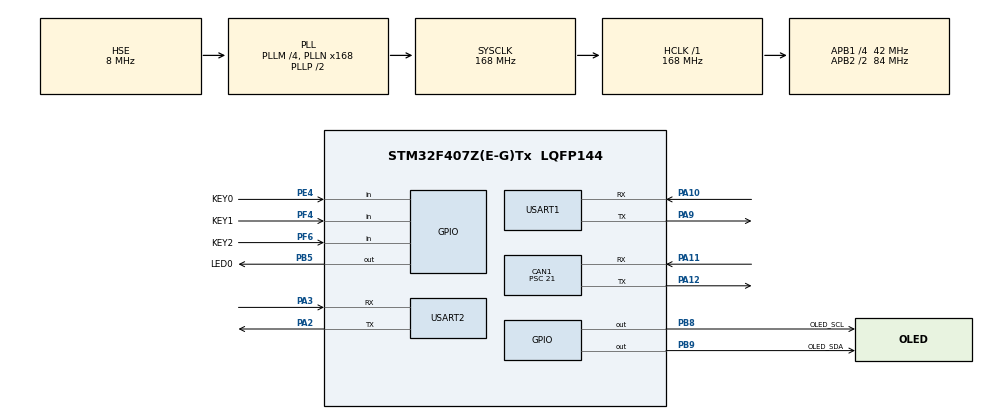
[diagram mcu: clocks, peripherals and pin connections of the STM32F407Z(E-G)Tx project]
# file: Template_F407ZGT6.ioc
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CAN1.BS1=CAN_BS1_13TQ
CAN1.BS2=CAN_BS2_2TQ
CAN1.CalculateBaudRate=125000
CAN1.CalculateTimeBit=8000
CAN1.CalculateTimeQuantum=500.0
CAN1.Mode=CAN_MODE_NORMAL
CAN1.NART=ENABLE
CAN1.Prescaler=21
CAN1.SJW=CAN_SJW_2TQ
Dma.Request0=USART1_RX
Dma.Request1=USART1_TX
Dma.Request2=USART2_RX
Dma.Request3=USART2_TX
Dma.USART1_RX.0.Direction=DMA_PERIPH_TO_MEMORY
Dma.USART1_RX.0.FIFOMode=DMA_FIFOMODE_DISABLE
Dma.USART1_RX.0.Instance=DMA2_Stream2
Dma.USART1_RX.0.MemDataAlignment=DMA_MDATAALIGN_BYTE
Dma.USART1_RX.0.MemInc=DMA_MINC_ENABLE
Dma.USART1_RX.0.Mode=DMA_NORMAL
Dma.USART1_RX.0.PeriphDataAlignment=DMA_PDATAALIGN_BYTE
Dma.USART1_RX.0.PeriphInc=DMA_PINC_DISABLE
Dma.USART1_RX.0.Priority=DMA_PRIORITY_LOW
Dma.USART1_TX.1.Direction=DMA_MEMORY_TO_PERIPH
Dma.USART1_TX.1.FIFOMode=DMA_FIFOMODE_DISABLE
Dma.USART1_TX.1.Instance=DMA2_Stream7
Dma.USART1_TX.1.MemDataAlignment=DMA_MDATAALIGN_BYTE
Dma.USART1_TX.1.MemInc=DMA_MINC_ENABLE
Dma.USART1_TX.1.Mode=DMA_NORMAL
Dma.USART1_TX.1.PeriphDataAlignment=DMA_PDATAALIGN_BYTE
Dma.USART1_TX.1.PeriphInc=DMA_PINC_DISABLE
Dma.USART1_TX.1.Priority=DMA_PRIORITY_LOW
Dma.USART2_RX.2.Direction=DMA_PERIPH_TO_MEMORY
Dma.USART2_RX.2.FIFOMode=DMA_FIFOMODE_DISABLE
Dma.USART2_RX.2.Instance=DMA1_Stream5
Dma.USART2_RX.2.MemDataAlignment=DMA_MDATAALIGN_BYTE
Dma.USART2_RX.2.MemInc=DMA_MINC_ENABLE
Dma.USART2_RX.2.Mode=DMA_NORMAL
Dma.USART2_RX.2.PeriphDataAlignment=DMA_PDATAALIGN_BYTE
Dma.USART2_RX.2.PeriphInc=DMA_PINC_DISABLE
Dma.USART2_RX.2.Priority=DMA_PRIORITY_LOW
Dma.USART2_TX.3.Direction=DMA_MEMORY_TO_PERIPH
Dma.USART2_TX.3.FIFOMode=DMA_FIFOMODE_DISABLE
Dma.USART2_TX.3.Instance=DMA1_Stream6
Dma.USART2_TX.3.MemDataAlignment=DMA_MDATAALIGN_BYTE
Dma.USART2_TX.3.MemInc=DMA_MINC_ENABLE
Dma.USART2_TX.3.Mode=DMA_NORMAL
Dma.USART2_TX.3.PeriphDataAlignment=DMA_PDATAALIGN_BYTE
Dma.USART2_TX.3.PeriphInc=DMA_PINC_DISABLE
Dma.USART2_TX.3.Priority=DMA_PRIORITY_LOW
Mcu.Family=STM32F4
Mcu.Name=STM32F407Z(E-G)Tx
Mcu.Package=LQFP144
NVIC.DMA1_Stream5_IRQn=true\:0\:0\:false\:false\:true\:false\:true\:true
NVIC.DMA1_Stream6_IRQn=true\:0\:0\:false\:false\:true\:false\:true\:true
NVIC.DMA2_Stream2_IRQn=true\:0\:0\:false\:false\:true\:false\:true\:true
NVIC.DMA2_Stream7_IRQn=true\:0\:0\:false\:false\:true\:false\:true\:true
NVIC.PriorityGroup=NVIC_PRIORITYGROUP_2
NVIC.TIM6_DAC_IRQn=true\:0\:0\:true\:false\:true\:true\:true\:true
NVIC.TIM7_IRQn=true\:0\:0\:false\:false\:true\:true\:true\:true
NVIC.TIM8_UP_TIM13_IRQn=true\:3\:0\:false\:false\:true\:false\:true\:true
NVIC.TimeBase=TIM8_UP_TIM13_IRQn
NVIC.TimeBaseIP=TIM13
NVIC.USART1_IRQn=true\:0\:0\:false\:false\:true\:true\:true\:true
NVIC.USART2_IRQn=true\:0\:0\:false\:false\:true\:true\:true\:true
PA10.Mode=Asynchronous
PA10.Signal=USART1_RX
PA11.GPIO_PuPd=GPIO_PULLUP
PA11.Mode=CAN_Activate
PA11.Signal=CAN1_RX
PA12.Mode=CAN_Activate
PA12.Signal=CAN1_TX
PA13.Mode=Serial_Wire
PA13.Signal=SYS_JTMS-SWDIO
PA14.Mode=Serial_Wire
PA14.Signal=SYS_JTCK-SWCLK
PA2.Mode=Asynchronous
PA2.Signal=USART2_TX
PA3.Mode=Asynchronous
PA3.Signal=USART2_RX
PA9.Mode=Asynchronous
PA9.Signal=USART1_TX
PB5.GPIO_Label=LED0
PB5.PinState=GPIO_PIN_RESET
PB5.Signal=GPIO_Output
PB8.GPIO_Label=OLED_SCL
PB8.GPIO_Speed=GPIO_SPEED_FREQ_HIGH
PB8.Signal=GPIO_Output
PB9.GPIO_Label=OLED_SDA
PB9.GPIO_Speed=GPIO_SPEED_FREQ_HIGH
PB9.Signal=GPIO_Output
PC14-OSC32_IN.Mode=LSE-External-Oscillator
PC14-OSC32_IN.Signal=RCC_OSC32_IN
PC15-OSC32_OUT.Mode=LSE-External-Oscillator
PC15-OSC32_OUT.Signal=RCC_OSC32_OUT
PE4.GPIO_Label=KEY0
PE4.GPIO_PuPd=GPIO_PULLUP
PE4.Signal=GPIO_Input
PF4.GPIO_Label=KEY1
PF4.GPIO_PuPd=GPIO_PULLUP
PF4.Signal=GPIO_Input
PF6.GPIO_Label=KEY2
PF6.GPIO_PuPd=GPIO_PULLUP
PF6.Signal=GPIO_Input
PH0-OSC_IN.Mode=HSE-External-Oscillator
PH0-OSC_IN.Signal=RCC_OSC_IN
PH1-OSC_OUT.Mode=HSE-External-Oscillator
PH1-OSC_OUT.Signal=RCC_OSC_OUT
ProjectManager.HeapSize=0x200
ProjectManager.StackSize=0x400
ProjectManager.TargetToolchain=MDK-ARM V5.32
RCC.48MHZClocksFreq_Value=84000000
RCC.AHBFreq_Value=168000000
RCC.APB1CLKDivider=RCC_HCLK_DIV4
RCC.APB1Freq_Value=42000000
RCC.APB1TimFreq_Value=84000000
RCC.APB2CLKDivider=RCC_HCLK_DIV2
RCC.APB2Freq_Value=84000000
RCC.APB2TimFreq_Value=168000000
RCC.CortexFreq_Value=168000000
RCC.HCLKFreq_Value=168000000
RCC.HSE_VALUE=8000000
RCC.HSI_VALUE=16000000
RCC.PLLM=4
RCC.PLLN=168
RCC.PLLSourceVirtual=RCC_PLLSOURCE_HSE
RCC.SYSCLKFreq_VALUE=168000000
RCC.SYSCLKSource=RCC_SYSCLKSOURCE_PLLCLK
RCC.VCOOutputFreq_Value=336000000
TIM6.AutoReloadPreload=TIM_AUTORELOAD_PRELOAD_ENABLE
TIM6.Period=1000-1
TIM6.Prescaler=84-1
TIM7.AutoReloadPreload=TIM_AUTORELOAD_PRELOAD_ENABLE
TIM7.Period=20000-1
TIM7.Prescaler=84-1
USART1.VirtualMode=VM_ASYNC
USART2.VirtualMode=VM_ASYNC
VP_SYS_VS_tim13.Mode=TIM13
VP_TIM6_VS_ClockSourceINT.Mode=Enable_Timer
VP_TIM7_VS_ClockSourceINT.Mode=Enable_Timer
board=custom

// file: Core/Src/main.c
/* USER CODE BEGIN Header */
/**
  ******************************************************************************
  * @file           : main.c
  * @brief          : Main program body
  ******************************************************************************
  * @attention
  *
  * Copyright (c) 2026 STMicroelectronics.
  * All rights reserved.
  *
  * This software is licensed under terms that can be found in the LICENSE file
  * in the root directory of this software component.
  * If no LICENSE file comes with this software, it is provided AS-IS.
  *
  ******************************************************************************
  */
/* USER CODE END Header */
#include "main.h"
#include "can.h"
#include "dma.h"
#include "tim.h"
#include "usart.h"
#include "gpio.h"

/* USER CODE BEGIN Includes */
#include "Mymain.h"
#include "MyISR.h"

/* USER CODE END Includes */

void SystemClock_Config(void);

int main(void)
{

  /* MCU Configuration--------------------------------------------------------*/

  /* Reset of all peripherals, Initializes the Flash interface and the Systick. */
  HAL_Init();

  /* Configure the system clock */
  SystemClock_Config();

  /* Initialize all configured peripherals */
  MX_GPIO_Init();
  MX_DMA_Init();
  MX_TIM6_Init();
  MX_TIM7_Init();
  MX_USART1_UART_Init();
  MX_USART2_UART_Init();
  MX_CAN1_Init();
  /* USER CODE BEGIN 2 */
  Mymain();

  /* USER CODE END 2 */

  /* Infinite loop */
  while (1)
  {

  }
}

void SystemClock_Config(void)
{
  RCC_OscInitTypeDef RCC_OscInitStruct = {0};
  RCC_ClkInitTypeDef RCC_ClkInitStruct = {0};

  /** Configure the main internal regulator output voltage
  */
  __HAL_RCC_PWR_CLK_ENABLE();
  __HAL_PWR_VOLTAGESCALING_CONFIG(PWR_REGULATOR_VOLTAGE_SCALE1);

  /** Initializes the RCC Oscillators according to the specified parameters
  * in the RCC_OscInitTypeDef structure.
  */
  RCC_OscInitStruct.OscillatorType = RCC_OSCILLATORTYPE_HSE;
  RCC_OscInitStruct.HSEState = RCC_HSE_ON;
  RCC_OscInitStruct.PLL.PLLState = RCC_PLL_ON;
  RCC_OscInitStruct.PLL.PLLSource = RCC_PLLSOURCE_HSE;
  RCC_OscInitStruct.PLL.PLLM = 4;
  RCC_OscInitStruct.PLL.PLLN = 168;
  RCC_OscInitStruct.PLL.PLLP = RCC_PLLP_DIV2;
  RCC_OscInitStruct.PLL.PLLQ = 4;
  if (HAL_RCC_OscConfig(&RCC_OscInitStruct) != HAL_OK)
  {
    Error_Handler();
  }

  /** Initializes the CPU, AHB and APB buses clocks
  */
  RCC_ClkInitStruct.ClockType = RCC_CLOCKTYPE_HCLK|RCC_CLOCKTYPE_SYSCLK
                              |RCC_CLOCKTYPE_PCLK1|RCC_CLOCKTYPE_PCLK2;
  RCC_ClkInitStruct.SYSCLKSource = RCC_SYSCLKSOURCE_PLLCLK;
  RCC_ClkInitStruct.AHBCLKDivider = RCC_SYSCLK_DIV1;
  RCC_ClkInitStruct.APB1CLKDivider = RCC_HCLK_DIV4;
  RCC_ClkInitStruct.APB2CLKDivider = RCC_HCLK_DIV2;

  if (HAL_RCC_ClockConfig(&RCC_ClkInitStruct, FLASH_LATENCY_5) != HAL_OK)
  {
    Error_Handler();
  }
}

void HAL_TIM_PeriodElapsedCallback(TIM_HandleTypeDef *htim)
{
  if (htim->Instance == TIM13)
  {
    HAL_IncTick();
  }
  /* USER CODE BEGIN Callback 1 */
  if (htim->Instance == TIM6) MyISR_TIM6_1ms();
  if (htim->Instance == TIM7) MyISR_TIM7_20ms();

  /* USER CODE END Callback 1 */
}

void Error_Handler(void)
{
  __disable_irq();
  while (1)
  {
  }
}
